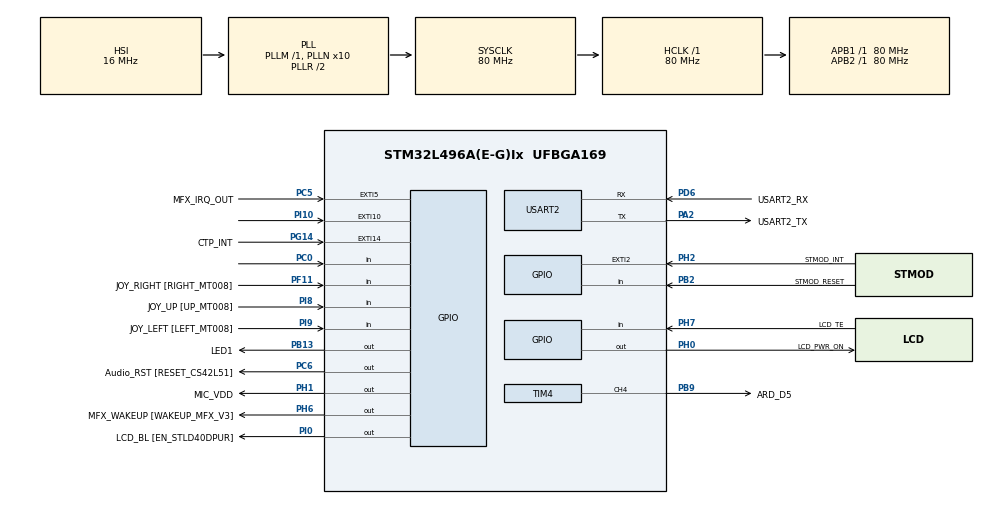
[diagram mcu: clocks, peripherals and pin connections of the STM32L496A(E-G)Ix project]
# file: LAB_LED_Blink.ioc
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Mcu.Family=STM32L4
Mcu.Name=STM32L496A(E-G)Ix
Mcu.Package=UFBGA169
NVIC.EXTI15_10_IRQn=true\:0\:0\:false\:false\:true\:true\:true
NVIC.PriorityGroup=NVIC_PRIORITYGROUP_4
NVIC.TIM3_IRQn=true\:0\:0\:false\:false\:true\:true\:true
NVIC.USART2_IRQn=true\:0\:0\:false\:false\:true\:true\:true
PA0.GPIO_Label=STMOD_PWM
PA0.Signal=SYS_WKUP1
PA1.GPIO_Label=ARD_A4
PA1.Signal=ADCx_IN6
PA10.GPIO_Label=USB_OTGFS_ID
PA10.Signal=USB_OTG_FS_ID
PA11.GPIO_Label=USB_OTGFS_DM
PA11.Signal=USB_OTG_FS_DM
PA12.GPIO_Label=USB_OTGFS_DP
PA12.Signal=USB_OTG_FS_DP
PA13\ (JTMS/SWDIO).GPIO_Label=SWDIO
PA13\ (JTMS/SWDIO).Mode=Serial_Wire
PA13\ (JTMS/SWDIO).Signal=SYS_JTMS-SWDIO
PA14\ (JTCK/SWCLK).GPIO_Label=SWCLK
PA14\ (JTCK/SWCLK).Mode=Serial_Wire
PA14\ (JTCK/SWCLK).Signal=SYS_JTCK-SWCLK
PA15\ (JTDI).GPIO_Label=ARD_D10
PA15\ (JTDI).Signal=SPI1_NSS
PA2.GPIO_Label=USART2_TX
PA2.Mode=Asynchronous
PA2.Signal=USART2_TX
PA3.GPIO_Label=QSPI_CLK [MX25R6435FM2IL0_SCLK]
PA3.Signal=QUADSPI_CLK
PA4.GPIO_Label=STMOD_ADC
PA4.Signal=ADCx_IN9
PA5.GPIO_Label=ARD_D13
PA5.Signal=SPI1_SCK
PA6.GPIO_Label=QSPI_BK1_IO3 [MX25R6435FM2IL0_SIO3]
PA6.Signal=QUADSPI_BK1_IO3
PA7.GPIO_Label=QSPI_BK1_IO2 [MX25R6435FM2IL0_SIO2]
PA7.Signal=QUADSPI_BK1_IO2
PA8.GPIO_Label=DCMI_CLK
PA8.Signal=LPTIM2_OUT
PA9.GPIO_Label=USB_OTGFS_VBUS
PA9.Signal=USB_OTG_FS_VBUS
PB0.GPIO_Label=QSPI_BK1_IO1 [MX25R6435FM2IL0_SIO1]
PB0.Signal=QUADSPI_BK1_IO1
PB1.GPIO_Label=QSPI_BK1_IO0 [MX25R6435FM2IL0_SIO0]
PB1.Signal=QUADSPI_BK1_IO0
PB10.GPIO_Label=SAI1_CKA [SLCK_CS42L51]
PB10.Signal=SAI1_SCK_A
PB11.GPIO_Label=QSPI_BK1_NCS [MX25R6435FM2IL0_CS]
PB11.Signal=QUADSPI_BK1_NCS
PB12.GPIO_Label=DFDATIN1
PB12.Signal=S_DATAIN1DFSDM1
PB13.GPIO_Label=LED1
PB13.GPIO_ModeDefaultOutputPP=GPIO_MODE_OUTPUT_PP
PB13.GPIO_PuPd=GPIO_NOPULL
PB13.Signal=GPIO_Output
PB14.GPIO_Label=I2C2_SDA [CS42L51_SDA]
PB14.Signal=I2C2_SDA
PB15.GPIO_Label=SPI2_MOSI
PB15.Signal=SPI2_MOSI
PB2.GPIO_Label=STMOD_RESET
PB2.Signal=GPIO_Input
PB3\ (JTDO/TRACESWO).GPIO_Label=SWO
PB3\ (JTDO/TRACESWO).Signal=SYS_JTDO-SWO
PB4\ (NJTRST).GPIO_Label=ARD_D12
PB4\ (NJTRST).Signal=SPI1_MISO
PB5.GPIO_Label=ARD_D11
PB5.Signal=SPI1_MOSI
PB6.GPIO_Label=USART1_TX
PB6.Signal=USART1_TX
PB7.GPIO_Label=I2C1_SDA
PB7.Signal=I2C1_SDA
PB8.GPIO_Label=I2C1_SCL
PB8.Signal=I2C1_SCL
PB9.GPIO_Label=ARD_D5
PB9.Signal=S_TIM4_CH4
PC0.GPIO_PuPd=GPIO_NOPULL
PC0.Signal=GPIO_Input
PC1.Signal=ADCx_IN2
PC10.GPIO_Label=uSD_D2
PC10.Signal=SDMMC1_D2
PC11.GPIO_Label=uSD_D3
PC11.Signal=SDMMC1_D3
PC12.GPIO_Label=uSD_CLK
PC12.Signal=SDMMC1_CK
PC13.GPIO_Label=JOY_SEL [Selection_MT008]
PC13.Signal=SYS_WKUP2
PC14-OSC32_IN\ (PC14).Mode=LSE-External-Oscillator
PC14-OSC32_IN\ (PC14).Signal=RCC_OSC32_IN
PC15-OSC32_OUT\ (PC15).Mode=LSE-External-Oscillator
PC15-OSC32_OUT\ (PC15).Signal=RCC_OSC32_OUT
PC2.GPIO_Label=DF_CKOUT
PC2.Signal=S_CKOUTDFSDM1
PC3.GPIO_Label=ARD_A2
PC3.Signal=ADCx_IN4
PC4.GPIO_Label=ARD_A0
PC4.Signal=ADCx_IN13
PC5.GPIO_Label=MFX_IRQ_OUT
PC5.Signal=GPXTI5
PC6.GPIO_Label=Audio_RST [RESET_CS42L51]
PC6.Signal=GPIO_Output
PC7.GPIO_Label=DATIN3 [DOUT_MP34DT01TR]
PC7.Signal=S_DATAIN3DFSDM1
PC8.GPIO_Label=uSD_D0
PC8.Signal=SDMMC1_D0
PC9.GPIO_Label=uSD_D1
PC9.Signal=SDMMC1_D1
PD0.GPIO_Label=D2 [D2_ IS66WV51216EBLL]
PD0.Signal=FMC_D2_DA2
PD1.GPIO_Label=D3 [D3_IS66WV51216EBLL]
PD1.Signal=FMC_D3_DA3
PD10.GPIO_Label=D15 [D15_IS66WV51216EBLL]
PD10.Signal=FMC_D15_DA15
PD11.GPIO_Label=PSRAM_A16 [A16_IS66WV51216EBLL]
PD11.Signal=FMC_A16_CLE
PD12.GPIO_Label=PSRAM_A17 [A17_IS66WV51216EBLL]
PD12.Signal=FMC_A17_ALE
PD13.GPIO_Label=PSRAM_A18_LCD_RS [A18_IS66WV51216EBLL]
PD13.Signal=FMC_A18
PD14.GPIO_Label=D0 [D0_IS66WV51216EBLL]
PD14.Signal=FMC_D0_DA0
PD15.GPIO_Label=D1 [D1_IS66WV51216EBLL]
PD15.Signal=FMC_D1_DA1
PD2.GPIO_Label=uSD_CMD
PD2.Signal=SDMMC1_CMD
PD4.GPIO_Label=OE [OE_IS66WV51216EBLL]
PD4.Signal=FMC_NOE
PD5.GPIO_Label=WE [WE_IS66WV51216EBLL]
PD5.Signal=FMC_NWE
PD6.GPIO_Label=USART2_RX
PD6.Mode=Asynchronous
PD6.Signal=USART2_RX
PD7.GPIO_Label=LCD_NE
PD7.Signal=FMC_NE1
PD8.GPIO_Label=D13 [D13_IS66WV51216EBLL]
PD8.Signal=FMC_D13_DA13
PD9.GPIO_Label=D14 [D14_IS66WV51216EBLL]
PD9.Signal=FMC_D14_DA14
PE0.GPIO_Label=PSRAM_NBL0 [LB_IS66WV51216EBLL]
PE0.Signal=FMC_NBL0
PE1.GPIO_Label=PSRAM_NBL1 [UB_IS66WV51216EBLL]
PE1.Signal=FMC_NBL1
PE10.GPIO_Label=D7 [D7_IS66WV51216EBLL]
PE10.Signal=FMC_D7_DA7
PE11.GPIO_Label=D8  [D8_IS66WV51216EBLL]
PE11.Signal=FMC_D8_DA8
PE12.GPIO_Label=D9 [D9_IS66WV51216EBLL]
PE12.Signal=FMC_D9_DA9
PE13.GPIO_Label=D10 [D10_IS66WV51216EBLL]
PE13.Signal=FMC_D10_DA10
PE14.GPIO_Label=D11 [D11_IS66WV51216EBLL]
PE14.Signal=FMC_D11_DA11
PE15.GPIO_Label=D12 [D12_IS66WV51216EBLL]
PE15.Signal=FMC_D12_DA12
PE2.GPIO_Label=SAI1_MCKA [MCLK_CS42L51]
PE2.Signal=SAI1_MCLK_A
PE3.GPIO_Label=SAI1_SDB [SDOUT_CS42L51]
PE3.Signal=SAI1_SD_B
PE4.GPIO_Label=SAI1_FSA [LRCK_CS42L51]]
PE4.Signal=SAI1_FS_A
PE5.GPIO_Label=DCMI_D6
PE5.Signal=DCMI_D6
PE6.GPIO_Label=SAI1_SDA [SDIN_CS42L51]
PE6.Signal=SAI1_SD_A
PE7.GPIO_Label=D4 [D4_IS66WV51216EBLL]
PE7.Signal=FMC_D4_DA4
PE8.GPIO_Label=D5 [D5_IS66WV51216EBLL]
PE8.Signal=FMC_D5_DA5
PE9.GPIO_Label=D6 [D6_IS66WV51216EBLL]
PE9.Signal=FMC_D6_DA6
PF0.GPIO_Label=PSRAM_A0 [A0_IS66WV51216EBLL]
PF0.Signal=FMC_A0
PF1.GPIO_Label=PSRAM_A1 [A1_IS66WV51216EBLL]
PF1.Signal=FMC_A1
PF10.GPIO_Label=ARD_A3
PF10.Signal=ADC3_IN13
PF11.GPIO_Label=JOY_RIGHT [RIGHT_MT008]
PF11.GPIO_PuPd=GPIO_PULLDOWN
PF11.Signal=GPIO_Input
PF12.GPIO_Label=PSRAM_A6 [A6_IS66WV51216EBLL]
PF12.Signal=FMC_A6
PF13.GPIO_Label=PSRAM_A7 [A7_IS66WV51216EBLL]
PF13.Signal=FMC_A7
PF14.GPIO_Label=PSRAM_A8 [A8_IS66WV51216EBLL]
PF14.Signal=FMC_A8
PF15.GPIO_Label=PSRAM_A9 [A9_IS66WV51216EBLL]
PF15.Signal=FMC_A9
PF2.GPIO_Label=PSRAM_A2 [A2_IS66WV51216EBLL]
PF2.Signal=FMC_A2
PF3.GPIO_Label=PSRAM_A3 [A3_IS66WV51216EBLL]
PF3.Signal=FMC_A3
PF4.GPIO_Label=PSRAM_A4 [A4_IS66WV51216EBLL]
PF4.Signal=FMC_A4
PF5.GPIO_Label=PSRAM_A5 [A5_IS66WV51216EBLL]
PF5.Signal=FMC_A5
PG0.GPIO_Label=PSRAM_A10 [A10_IS66WV51216EBLL]
PG0.Signal=FMC_A10
PG1.GPIO_Label=PSRAM_A11 [A11_IS66WV51216EBLL]
PG1.Signal=FMC_A11
PG10.GPIO_Label=UART1_RX [STMOD+_UART]
PG10.Signal=USART1_RX
PG11.GPIO_Label=UART1_CTS [STMOD+_UART]
PG11.Signal=USART1_CTS
PG12.GPIO_Label=UART1_RTS [STMOD+_UART]
PG12.Signal=USART1_RTS
PG14.GPIO_Label=CTP_INT
PG14.Signal=GPXTI14
PG2.GPIO_Label=PSRAM_A12 [A12_IS66WV51216EBLL]
PG2.Signal=FMC_A12
PG3.GPIO_Label=PSRAM_A13 [A13_IS66WV51216EBLL]
PG3.Signal=FMC_A13
PG4.GPIO_Label=PSRAM_A14 [A14_IS66WV51216EBLL]
PG4.Signal=FMC_A14
PG5.GPIO_Label=PSRAM_A15 [A15_IS66WV51216EBLL]
PG5.Signal=FMC_A15
PG7.GPIO_Label=ARD_D1
PG7.Signal=LPUART1_TX
PG8.GPIO_Label=ARD_D0
PG8.Signal=LPUART1_RX
PG9.GPIO_Label=PSRAM_NE [CS1_IS66WV51216EBLL]
PG9.Signal=FMC_NE2
PH0-OSC_IN\ (PH0).GPIO_Label=LCD_PWR_ON
PH0-OSC_IN\ (PH0).Signal=GPIO_Output
PH1-OSC_OUT\ (PH1).GPIO_Label=MIC_VDD
PH1-OSC_OUT\ (PH1).Signal=GPIO_Output
PH10.GPIO_Label=DCMI_D1
PH10.Signal=DCMI_D1
PH11.GPIO_Label=DCMI_D2
PH11.Signal=DCMI_D2
PH12.GPIO_Label=DCMI_D3
PH12.Signal=DCMI_D3
PH13.GPIO_Label=ARD_D9
PH13.Signal=TIM8_CH1N
PH14.GPIO_Label=DCMI_D4
PH14.Signal=DCMI_D4
PH15.GPIO_Label=ARD_D3
PH15.Signal=TIM8_CH3N
PH2.GPIO_Label=STMOD_INT
PH2.Signal=GPXTI2
PH4.GPIO_Label=I2C2_SCL [SCL_CS42L51]
PH4.Signal=I2C2_SCL
PH5.GPIO_Label=DCMI_PIXCK
PH5.Signal=DCMI_PIXCLK
PH6.GPIO_Label=MFX_WAKEUP [WAKEUP_MFX_V3]
PH6.Signal=GPIO_Output
PH7.GPIO_Label=LCD_TE
PH7.Signal=GPIO_Input
PH8.GPIO_Label=DCMI_HSYNC
PH8.Signal=DCMI_HSYNC
PH9.GPIO_Label=DCMI_D0
PH9.Signal=DCMI_D0
PI0.GPIO_Label=LCD_BL [EN_STLD40DPUR]
PI0.Signal=GPIO_Output
PI1.GPIO_Label=SPI2_CLK [STMOD+_SPI]
PI1.Signal=SPI2_SCK
PI10.GPIO_PuPd=GPIO_PULLDOWN
PI10.Signal=GPXTI10
PI2.GPIO_Label=SPI2_MISO [STMOD+_SPI]
PI2.Signal=SPI2_MISO
PI4.GPIO_Label=DCMI_D5
PI4.Signal=DCMI_D5
PI5.GPIO_Label=DCMI_VSYNC
PI5.Signal=DCMI_VSYNC
PI6.GPIO_Label=ARD_D6
PI6.Signal=S_TIM8_CH2
PI7.GPIO_Label=DCMI_D7
PI7.Signal=DCMI_D7
PI8.GPIO_Label=JOY_UP [UP_MT008]
PI8.GPIO_PuPd=GPIO_PULLDOWN
PI8.Signal=GPIO_Input
PI9.GPIO_Label=JOY_LEFT [LEFT_MT008]
PI9.GPIO_PuPd=GPIO_PULLDOWN
PI9.Signal=GPIO_Input
ProjectManager.HeapSize=0x2000
ProjectManager.StackSize=0x2000
ProjectManager.TargetToolchain=STM32CubeIDE
RCC.ADCFreq_Value=160000000
RCC.AHBFreq_Value=80000000
RCC.APB1Freq_Value=80000000
RCC.APB1TimFreq_Value=80000000
RCC.APB2Freq_Value=80000000
RCC.APB2TimFreq_Value=80000000
RCC.CortexFreq_Value=80000000
RCC.HCLKFreq_Value=80000000
RCC.HSE_VALUE=8000000
RCC.HSI48_VALUE=48000000
RCC.HSI_VALUE=16000000
RCC.MSIClockRange=RCC_MSIRANGE_9
RCC.MSI_VALUE=24000000
RCC.PLLN=10
RCC.PLLSAI1N=20
RCC.PLLSourceVirtual=RCC_PLLSOURCE_HSI
RCC.SYSCLKFreq_VALUE=80000000
RCC.SYSCLKSource=RCC_SYSCLKSOURCE_PLLCLK
RCC.USBFreq_Value=160000000
RCC.VCOOutputFreq_Value=160000000
SH.ADCx_IN13.0=ADC1_IN13
SH.ADCx_IN2.0=ADC2_IN2
SH.ADCx_IN4.0=ADC1_IN4
SH.ADCx_IN6.0=ADC2_IN6
SH.ADCx_IN9.0=ADC2_IN9
SH.FMC_A0.0=FMC_A0
SH.FMC_A1.0=FMC_A1
SH.FMC_A10.0=FMC_A10
SH.FMC_A11.0=FMC_A11
SH.FMC_A12.0=FMC_A12
SH.FMC_A13.0=FMC_A13
SH.FMC_A14.0=FMC_A14
SH.FMC_A15.0=FMC_A15
SH.FMC_A16_CLE.0=FMC_A16
SH.FMC_A17_ALE.0=FMC_A17
SH.FMC_A18.0=FMC_A18
SH.FMC_A2.0=FMC_A2
SH.FMC_A3.0=FMC_A3
SH.FMC_A4.0=FMC_A4
SH.FMC_A5.0=FMC_A5
SH.FMC_A6.0=FMC_A6
SH.FMC_A7.0=FMC_A7
SH.FMC_A8.0=FMC_A8
SH.FMC_A9.0=FMC_A9
SH.FMC_D0_DA0.0=FMC_D0
SH.FMC_D10_DA10.0=FMC_D10
SH.FMC_D11_DA11.0=FMC_D11
SH.FMC_D12_DA12.0=FMC_D12
SH.FMC_D13_DA13.0=FMC_D13
SH.FMC_D14_DA14.0=FMC_D14
SH.FMC_D15_DA15.0=FMC_D15
SH.FMC_D1_DA1.0=FMC_D1
SH.FMC_D2_DA2.0=FMC_D2
SH.FMC_D3_DA3.0=FMC_D3
SH.FMC_D4_DA4.0=FMC_D4
SH.FMC_D5_DA5.0=FMC_D5
SH.FMC_D6_DA6.0=FMC_D6
SH.FMC_D7_DA7.0=FMC_D7
SH.FMC_D8_DA8.0=FMC_D8
SH.FMC_D9_DA9.0=FMC_D9
SH.FMC_NBL0.0=FMC_NBL0
SH.FMC_NBL1.0=FMC_NBL1
SH.FMC_NOE.0=FMC_NOE
SH.FMC_NWE.0=FMC_NWE
SH.S_CKOUTDFSDM1.0=DFSDM1_CKOUT
SH.S_DATAIN1DFSDM1.0=DFSDM1_DATIN1
SH.S_DATAIN3DFSDM1.0=DFSDM1_DATIN3
SH.S_TIM4_CH4.0=TIM4_CH4,PWM Generation4 CH4
SH.S_TIM8_CH2.0=TIM8_CH2
TIM3.Period=99
TIM3.Prescaler=79
TIM4.Channel-PWM\ Generation4\ CH4=TIM_CHANNEL_4
TIM4.Prescaler=79
TIM4.Pulse-PWM\ Generation4\ CH4=999
USART2.VirtualMode-Asynchronous=VM_ASYNC
VP_TIM3_VS_ClockSourceINT.Mode=Internal
VP_TIM4_VS_ClockSourceINT.Mode=Internal
board=STM32L496G-DISCO

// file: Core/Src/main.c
/* USER CODE BEGIN Header */
/**
  ******************************************************************************
  * @file           : main.c
  * @brief          : Main program body
  ******************************************************************************
  * @attention
  *
  * <h2><center>&copy; Copyright (c) 2021 STMicroelectronics.
  * All rights reserved.</center></h2>
  *
  * This software component is licensed by ST under BSD 3-Clause license,
  * the "License"; You may not use this file except in compliance with the
  * License. You may obtain a copy of the License at:
  *                        opensource.org/licenses/BSD-3-Clause
  *
  ******************************************************************************
  */
/* USER CODE END Header */
#include "main.h"
#include "tim.h"
#include "usart.h"
#include "gpio.h"

/* USER CODE BEGIN PV */
void HAL_GPIO_EXTI_Callback(uint16_t GPIO_Pin)
{
  HAL_GPIO_TogglePin(GPIOB,GPIO_PIN_13);
}
/* USER CODE END PV */

void SystemClock_Config(void);

int main(void)
{

  /* MCU Configuration--------------------------------------------------------*/

  /* Reset of all peripherals, Initializes the Flash interface and the Systick. */
  HAL_Init();

  /* Configure the system clock */
  SystemClock_Config();

  /* Initialize all configured peripherals */
  MX_GPIO_Init();
  MX_TIM3_Init();
  MX_USART2_UART_Init();
  MX_TIM4_Init();

  /* Infinite loop */
  while (1)
  {

  }
}

void SystemClock_Config(void)
{
  RCC_OscInitTypeDef RCC_OscInitStruct = {0};
  RCC_ClkInitTypeDef RCC_ClkInitStruct = {0};

  /** Configure the main internal regulator output voltage
  */
  if (HAL_PWREx_ControlVoltageScaling(PWR_REGULATOR_VOLTAGE_SCALE1) != HAL_OK)
  {
    Error_Handler();
  }
  /** Initializes the RCC Oscillators according to the specified parameters
  * in the RCC_OscInitTypeDef structure.
  */
  RCC_OscInitStruct.OscillatorType = RCC_OSCILLATORTYPE_HSI;
  RCC_OscInitStruct.HSIState = RCC_HSI_ON;
  RCC_OscInitStruct.HSICalibrationValue = RCC_HSICALIBRATION_DEFAULT;
  RCC_OscInitStruct.PLL.PLLState = RCC_PLL_ON;
  RCC_OscInitStruct.PLL.PLLSource = RCC_PLLSOURCE_HSI;
  RCC_OscInitStruct.PLL.PLLM = 1;
  RCC_OscInitStruct.PLL.PLLN = 10;
  RCC_OscInitStruct.PLL.PLLP = RCC_PLLP_DIV2;
  RCC_OscInitStruct.PLL.PLLQ = RCC_PLLQ_DIV2;
  RCC_OscInitStruct.PLL.PLLR = RCC_PLLR_DIV2;
  if (HAL_RCC_OscConfig(&RCC_OscInitStruct) != HAL_OK)
  {
    Error_Handler();
  }
  /** Initializes the CPU, AHB and APB buses clocks
  */
  RCC_ClkInitStruct.ClockType = RCC_CLOCKTYPE_HCLK|RCC_CLOCKTYPE_SYSCLK
                              |RCC_CLOCKTYPE_PCLK1|RCC_CLOCKTYPE_PCLK2;
  RCC_ClkInitStruct.SYSCLKSource = RCC_SYSCLKSOURCE_PLLCLK;
  RCC_ClkInitStruct.AHBCLKDivider = RCC_SYSCLK_DIV1;
  RCC_ClkInitStruct.APB1CLKDivider = RCC_HCLK_DIV1;
  RCC_ClkInitStruct.APB2CLKDivider = RCC_HCLK_DIV1;

  if (HAL_RCC_ClockConfig(&RCC_ClkInitStruct, FLASH_LATENCY_4) != HAL_OK)
  {
    Error_Handler();
  }
}

void Error_Handler(void)
{
  __disable_irq();
  while (1)
  {
  }
}

/************************ (C) COPYRIGHT STMicroelectronics *****END OF FILE****/
